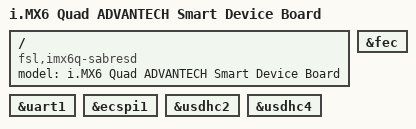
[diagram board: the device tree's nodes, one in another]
// SPDX-License-Identifier: GPL-2.0+
//
// Copyright 2012 Freescale Semiconductor, Inc.
// Copyright 2011 Linaro Ltd.

/dts-v1/;

#include "imx6q.dtsi"
#include "imx6qdl-advantech.dtsi"

/ {
	model = "i.MX6 Quad ADVANTECH Smart Device Board";
	compatible = "fsl,imx6q-sabresd", "fsl,imx6q";
};

&uart1 {
	status = "okay";
};

&ecspi1 {
	status = "okay";
};

&fec {
	status = "okay";
};

&usdhc2 {
	status = "okay";
};

&usdhc4 {
	status = "okay";
};
